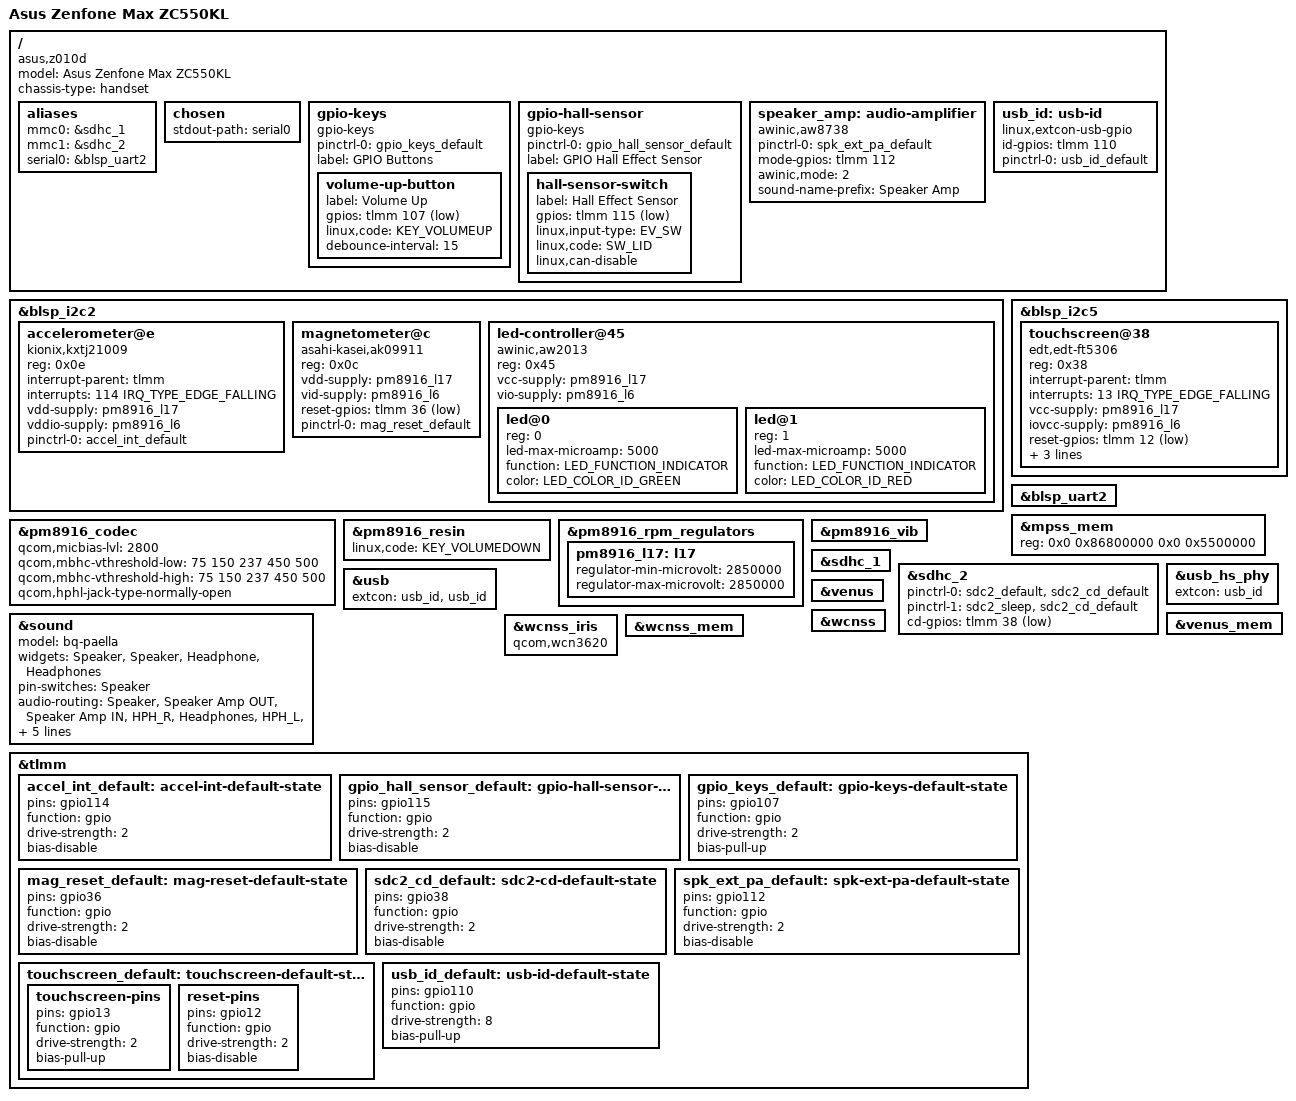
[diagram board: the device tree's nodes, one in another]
// SPDX-License-Identifier: GPL-2.0-only

/dts-v1/;

#include "msm8916-pm8916.dtsi"
#include "msm8916-modem-qdsp6.dtsi"

#include <dt-bindings/gpio/gpio.h>
#include <dt-bindings/input/input.h>
#include <dt-bindings/leds/common.h>

/ {
	model = "Asus Zenfone Max ZC550KL";
	compatible = "asus,z010d", "qcom,msm8916";
	chassis-type = "handset";

	aliases {
		mmc0 = &sdhc_1; /* eMMC */
		mmc1 = &sdhc_2; /* SD card */
		serial0 = &blsp_uart2;
	};

	chosen {
		stdout-path = "serial0";
	};

	gpio-keys {
		compatible = "gpio-keys";

		pinctrl-0 = <&gpio_keys_default>;
		pinctrl-names = "default";

		label = "GPIO Buttons";

		volume-up-button {
			label = "Volume Up";
			gpios = <&tlmm 107 GPIO_ACTIVE_LOW>;
			linux,code = <KEY_VOLUMEUP>;
			debounce-interval = <15>;
		};
	};

	gpio-hall-sensor {
		compatible = "gpio-keys";

		pinctrl-0 = <&gpio_hall_sensor_default>;
		pinctrl-names = "default";

		label = "GPIO Hall Effect Sensor";

		hall-sensor-switch {
			label = "Hall Effect Sensor";
			gpios = <&tlmm 115 GPIO_ACTIVE_LOW>;
			linux,input-type = <EV_SW>;
			linux,code = <SW_LID>;
			linux,can-disable;
		};
	};

	speaker_amp: audio-amplifier {
		compatible = "awinic,aw8738";

		pinctrl-0 = <&spk_ext_pa_default>;
		pinctrl-names = "default";

		mode-gpios = <&tlmm 112 GPIO_ACTIVE_HIGH>;
		awinic,mode = <2>;
		sound-name-prefix = "Speaker Amp";
	};

	usb_id: usb-id {
		compatible = "linux,extcon-usb-gpio";
		id-gpios = <&tlmm 110 GPIO_ACTIVE_HIGH>;
		pinctrl-0 = <&usb_id_default>;
		pinctrl-names = "default";
	};
};

&blsp_i2c2 {
	status = "okay";

	accelerometer@e {
		compatible = "kionix,kxtj21009";
		reg = <0x0e>;

		interrupt-parent = <&tlmm>;
		interrupts = <114 IRQ_TYPE_EDGE_FALLING>;

		vdd-supply = <&pm8916_l17>;
		vddio-supply = <&pm8916_l6>;

		pinctrl-0 = <&accel_int_default>;
		pinctrl-names = "default";
	};

	magnetometer@c {
		compatible = "asahi-kasei,ak09911";
		reg = <0x0c>;

		vdd-supply = <&pm8916_l17>;
		vid-supply = <&pm8916_l6>;

		reset-gpios = <&tlmm 36 GPIO_ACTIVE_LOW>;

		pinctrl-0 = <&mag_reset_default>;
		pinctrl-names = "default";
	};

	led-controller@45 {
		compatible = "awinic,aw2013";
		reg = <0x45>;
		#address-cells = <1>;
		#size-cells = <0>;

		vcc-supply = <&pm8916_l17>;
		vio-supply = <&pm8916_l6>;

		led@0 {
			reg = <0>;
			led-max-microamp = <5000>;
			function = LED_FUNCTION_INDICATOR;
			color = <LED_COLOR_ID_GREEN>;
		};

		led@1 {
			reg = <1>;
			led-max-microamp = <5000>;
			function = LED_FUNCTION_INDICATOR;
			color = <LED_COLOR_ID_RED>;
		};
	};
};

&blsp_i2c5 {
	status = "okay";

	touchscreen@38 {
		/* Actually ft5x46 */
		compatible = "edt,edt-ft5306";
		reg = <0x38>;

		interrupt-parent = <&tlmm>;
		interrupts = <13 IRQ_TYPE_EDGE_FALLING>;

		vcc-supply = <&pm8916_l17>;
		iovcc-supply = <&pm8916_l6>;

		reset-gpios = <&tlmm 12 GPIO_ACTIVE_LOW>;

		touchscreen-size-x = <720>;
		touchscreen-size-y = <1280>;

		pinctrl-0 = <&touchscreen_default>;
		pinctrl-names = "default";
	};
};

&blsp_uart2 {
	status = "okay";
};

&mpss_mem {
	reg = <0x0 0x86800000 0x0 0x5500000>;
};

&pm8916_codec {
	qcom,micbias-lvl = <2800>;
	qcom,mbhc-vthreshold-low = <75 150 237 450 500>;
	qcom,mbhc-vthreshold-high = <75 150 237 450 500>;
	qcom,hphl-jack-type-normally-open;
};

&pm8916_resin {
	linux,code = <KEY_VOLUMEDOWN>;
	status = "okay";
};

&pm8916_rpm_regulators {
	pm8916_l17: l17 {
		regulator-min-microvolt = <2850000>;
		regulator-max-microvolt = <2850000>;
	};
};

&pm8916_vib {
	status = "okay";
};

&sdhc_1 {
	status = "okay";
};

&sdhc_2 {
	pinctrl-0 = <&sdc2_default &sdc2_cd_default>;
	pinctrl-1 = <&sdc2_sleep &sdc2_cd_default>;
	pinctrl-names = "default", "sleep";

	cd-gpios = <&tlmm 38 GPIO_ACTIVE_LOW>;

	status = "okay";
};

&sound {
	model = "bq-paella";
	widgets =
		"Speaker", "Speaker",
		"Headphone", "Headphones";
	pin-switches = "Speaker";
	audio-routing =
		"Speaker", "Speaker Amp OUT",
		"Speaker Amp IN", "HPH_R",
		"Headphones", "HPH_L",
		"Headphones", "HPH_R",
		"AMIC1", "MIC BIAS Internal1",
		"AMIC2", "MIC BIAS Internal2",
		"AMIC3", "MIC BIAS Internal3";
	aux-devs = <&speaker_amp>;
};

&usb {
	extcon = <&usb_id>, <&usb_id>;
	status = "okay";
};

&usb_hs_phy {
	extcon = <&usb_id>;
};

&venus {
	status = "okay";
};

&venus_mem {
	status = "okay";
};

&wcnss {
	status = "okay";
};

&wcnss_iris {
	compatible = "qcom,wcn3620";
};

&wcnss_mem {
	status = "okay";
};

&tlmm {
	accel_int_default: accel-int-default-state {
		pins = "gpio114";
		function = "gpio";
		drive-strength = <2>;
		bias-disable;
	};

	gpio_hall_sensor_default: gpio-hall-sensor-default-state {
		pins = "gpio115";
		function = "gpio";
		drive-strength = <2>;
		bias-disable;
	};

	gpio_keys_default: gpio-keys-default-state {
		pins = "gpio107";
		function = "gpio";
		drive-strength = <2>;
		bias-pull-up;
	};

	mag_reset_default: mag-reset-default-state {
		pins = "gpio36";
		function = "gpio";
		drive-strength = <2>;
		bias-disable;
	};

	sdc2_cd_default: sdc2-cd-default-state {
		pins = "gpio38";
		function = "gpio";
		drive-strength = <2>;
		bias-disable;
	};

	spk_ext_pa_default: spk-ext-pa-default-state {
		pins = "gpio112";
		function = "gpio";
		drive-strength = <2>;
		bias-disable;
	};

	touchscreen_default: touchscreen-default-state {
		touchscreen-pins {
			pins = "gpio13";
			function = "gpio";
			drive-strength = <2>;
			bias-pull-up;
		};

		reset-pins {
			pins = "gpio12";
			function = "gpio";
			drive-strength = <2>;
			bias-disable;
		};
	};

	usb_id_default: usb-id-default-state {
		pins = "gpio110";
		function = "gpio";
		drive-strength = <8>;
		bias-pull-up;
	};
};
